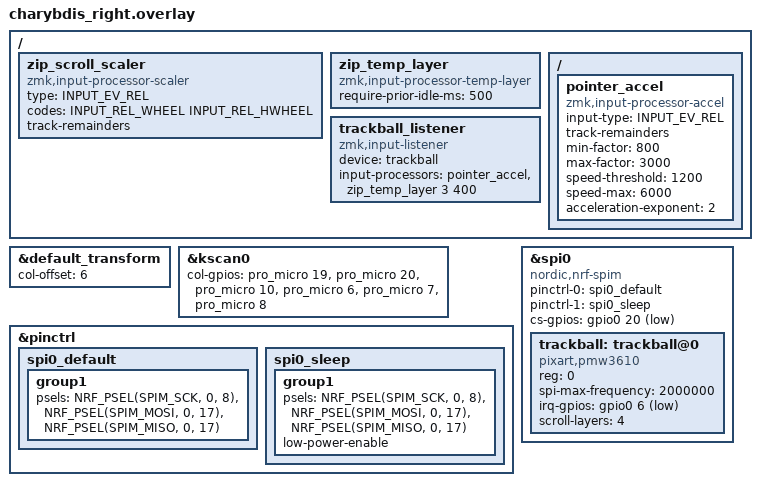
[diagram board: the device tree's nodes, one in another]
/*
 * Copyright (c) 2020 ZMK Contributors
 *
 * SPDX-License-Identifier: MIT
 */
 
#include "charybdis.dtsi"
#include <input/processors.dtsi>
#include <behaviors/input_gestures_accel.dtsi>

&default_transform {
    col-offset = <6>;
};

&kscan0 {
	col-gpios
		= <&pro_micro 19 (GPIO_ACTIVE_HIGH | GPIO_PULL_DOWN)>
		, <&pro_micro 20 (GPIO_ACTIVE_HIGH | GPIO_PULL_DOWN)>
		, <&pro_micro 10 (GPIO_ACTIVE_HIGH | GPIO_PULL_DOWN)>
		, <&pro_micro 6 (GPIO_ACTIVE_HIGH | GPIO_PULL_DOWN)>
		, <&pro_micro 7 (GPIO_ACTIVE_HIGH | GPIO_PULL_DOWN)>
		, <&pro_micro 8 (GPIO_ACTIVE_HIGH | GPIO_PULL_DOWN)>
		;
};



// trackball bus
&pinctrl {
    spi0_default: spi0_default {
        group1 {
            psels = <NRF_PSEL(SPIM_SCK, 0, 8)>,
                <NRF_PSEL(SPIM_MOSI, 0, 17)>,
                <NRF_PSEL(SPIM_MISO, 0, 17)>;
        };
    };

    spi0_sleep: spi0_sleep {
        group1 {
            psels = <NRF_PSEL(SPIM_SCK, 0, 8)>,
                <NRF_PSEL(SPIM_MOSI, 0, 17)>,
                <NRF_PSEL(SPIM_MISO, 0, 17)>;
            low-power-enable;
        };
    };
};

&spi0 {
    status = "okay";
    compatible = "nordic,nrf-spim";
    pinctrl-0 = <&spi0_default>;
    pinctrl-1 = <&spi0_sleep>;
    pinctrl-names = "default", "sleep";
    cs-gpios = <&gpio0 20 GPIO_ACTIVE_LOW>;

    trackball: trackball@0 {
        status = "okay";
        compatible = "pixart,pmw3610";
        reg = <0>;
        spi-max-frequency = <2000000>;
        irq-gpios = <&gpio0 6 (GPIO_ACTIVE_LOW | GPIO_PULL_UP)>;
        scroll-layers = <4>;
    };
};

#include <zephyr/dt-bindings/input/input-event-codes.h>

/ {
    zip_scroll_scaler: zip_scroll_scaler {
        compatible = "zmk,input-processor-scaler";
        #input-processor-cells = <2>;
        type = <INPUT_EV_REL>;
        codes = <INPUT_REL_WHEEL INPUT_REL_HWHEEL>;
        track-remainders;
    };
};


/ {
    zip_temp_layer: zip_temp_layer {
        compatible = "zmk,input-processor-temp-layer";
        #input-processor-cells = <2>;
        require-prior-idle-ms = <500>;
        
    };
#include <input/processors.dtsi>

/ {
    pointer_accel: pointer_accel {
        compatible = "zmk,input-processor-accel";
        #input-processor-cells = <0>;
        input-type = <INPUT_EV_REL>;
        track-remainders;
        // Настройки акселерации для прокрутки:
        // min-factor — множитель на очень медленной скорости (0.8x)
        min-factor = <800>;
        // max-factor — максимальный множитель (3.0x)
        max-factor = <3000>;
        // speed-threshold — скорость (в counts/sec), при которой достигается 1x
        speed-threshold = <1200>;
        // speed-max — скорость, при которой достигается max-factor
        speed-max = <6000>;
        // acceleration-exponent — кривая: 1 = линейная, 2 = квадратичная
        acceleration-exponent = <2>;
    };
};
    trackball_listener {
    compatible = "zmk,input-listener";
    device = <&trackball>;
    input-processors = <&pointer_accel &zip_temp_layer 3 400>;
};
};
